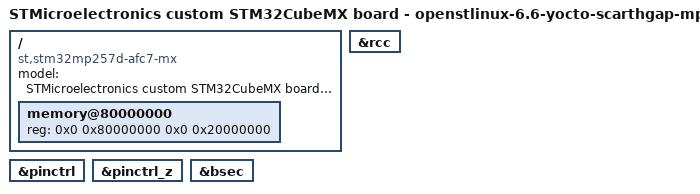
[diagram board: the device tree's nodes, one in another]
// SPDX-License-Identifier: (GPL-2.0-only OR BSD-3-Clause)
/*
 * Copyright (C) 2026, STMicroelectronics - All Rights Reserved
 * Author: STM32CubeMX code generation for STMicroelectronics.
 */

/* For more information on Device Tree configuration, please refer to
 * https://wiki.st.com/stm32mpu/wiki/Category:Device_tree_configuration
 */

/dts-v1/;

#include <dt-bindings/pinctrl/stm32-pinfunc.h>
#include <dt-bindings/clock/stm32mp25-clksrc.h>
#include "stm32mp257.dtsi"
#include "stm32mp257d-afc7-mx-rcc.dtsi"
#include "stm32mp257d-afc7-mx-resmem.dtsi"
#include "stm32mp257d-afc7-mx-rif.dtsi"
#include "stm32mp25xxak-pinctrl.dtsi"

/* USER CODE BEGIN includes */
/* USER CODE END includes */

/ {
	model = "STMicroelectronics custom STM32CubeMX board - openstlinux-6.6-yocto-scarthgap-mpu-v26.02.18";
	compatible = "st,stm32mp257d-afc7-mx", "st,stm32mp257";

	memory@80000000 {
		device_type = "memory";
		reg = <0x0 0x80000000 0x0 0x20000000>;

		/* USER CODE BEGIN memory */
		/* USER CODE END memory */
	};

	/* USER CODE BEGIN root */
	/* USER CODE END root */

}; /*root*/

&pinctrl {
	/* USER CODE BEGIN pinctrl */
	/* USER CODE END pinctrl */
};

&pinctrl_z {
	/* USER CODE BEGIN pinctrl_z */
	/* USER CODE END pinctrl_z */
};

&bsec {
	status = "okay";

	/* USER CODE BEGIN bsec */
	/* USER CODE END bsec */
};

&rcc {
	status = "okay";

	/* USER CODE BEGIN rcc */
	/* USER CODE END rcc */
};

/* USER CODE BEGIN addons */
/* USER CODE END addons */

